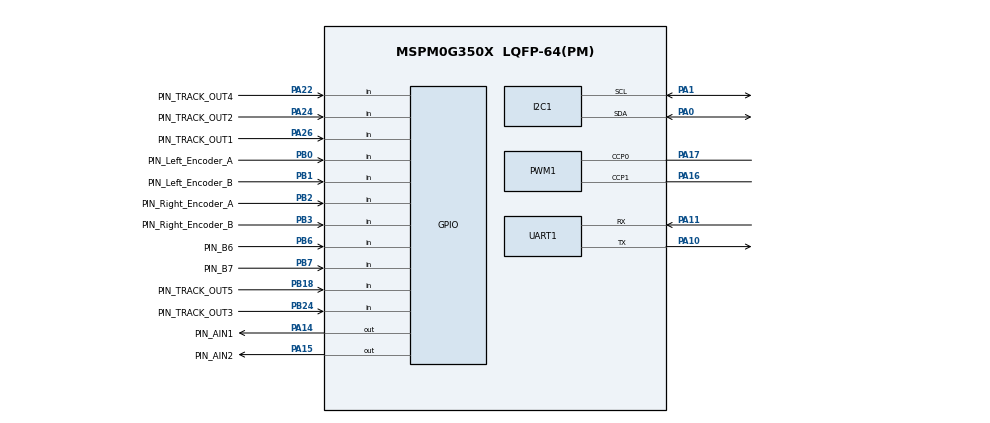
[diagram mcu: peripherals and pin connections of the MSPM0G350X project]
/**
 * @cliArgs --device "MSPM0G350X" --part "Default" --package "LQFP-64(PM)" --product "mspm0_sdk@2.10.00.04"
 * @versions {"tool":"1.26.2+4477"}
 */

/**
 * Import the modules used in this configuration.
 */
const Board  = scripting.addModule("/ti/driverlib/Board");
const GPIO   = scripting.addModule("/ti/driverlib/GPIO", {}, false);
const GPIO1  = GPIO.addInstance();
const GPIO2  = GPIO.addInstance();
const GPIO3  = GPIO.addInstance();
const GPIO4  = GPIO.addInstance();
const GPIO5  = GPIO.addInstance();
const GPIO6  = GPIO.addInstance();
const GPIO7  = GPIO.addInstance();
const GPIO8  = GPIO.addInstance();
const GPIO9  = GPIO.addInstance();
const GPIO10 = GPIO.addInstance();
const GPIO11 = GPIO.addInstance();
const GPIO12 = GPIO.addInstance();
const GPIO13 = GPIO.addInstance();
const GPIO14 = GPIO.addInstance();
const GPIO15 = GPIO.addInstance();
const GPIO16 = GPIO.addInstance();
const I2C    = scripting.addModule("/ti/driverlib/I2C", {}, false);
const I2C1   = I2C.addInstance();
const PWM    = scripting.addModule("/ti/driverlib/PWM", {}, false);
const PWM1   = PWM.addInstance();
const SYSCTL = scripting.addModule("/ti/driverlib/SYSCTL");
const TIMER  = scripting.addModule("/ti/driverlib/TIMER", {}, false);
const TIMER1 = TIMER.addInstance();
const UART   = scripting.addModule("/ti/driverlib/UART", {}, false);
const UART1  = UART.addInstance();

/**
 * Write custom configuration values to the imported modules.
 */
const divider9       = system.clockTree["UDIV"];
divider9.divideValue = 2;

const mux4       = system.clockTree["EXHFMUX"];
mux4.inputSelect = "EXHFMUX_XTAL";

const mux8       = system.clockTree["HSCLKMUX"];
mux8.inputSelect = "HSCLKMUX_SYSPLL2X";

const mux12       = system.clockTree["SYSPLLMUX"];
mux12.inputSelect = "zSYSPLLMUX_HFCLK";

const pinFunction4        = system.clockTree["HFXT"];
pinFunction4.inputFreq    = 40;
pinFunction4.enable       = true;
pinFunction4.HFXTStartup  = 10;
pinFunction4.HFCLKMonitor = true;


GPIO1.$name                              = "LED1";
GPIO1.port                               = "PORTB";
GPIO1.associatedPins[0].internalResistor = "PULL_DOWN";
GPIO1.associatedPins[0].$name            = "PIN_B22";
GPIO1.associatedPins[0].assignedPin      = "22";

GPIO2.$name                         = "AIN1";
GPIO2.port                          = "PORTA";
GPIO2.associatedPins[0].$name       = "PIN_AIN1";
GPIO2.associatedPins[0].pin.$assign = "PA14";

GPIO3.$name                         = "AIN2";
GPIO3.port                          = "PORTA";
GPIO3.associatedPins[0].$name       = "PIN_AIN2";
GPIO3.associatedPins[0].pin.$assign = "PA15";

GPIO4.$name                   = "BIN1";
GPIO4.port                    = "PORTA";
GPIO4.associatedPins[0].$name = "PIN_BIN1";

GPIO5.$name                   = "BIN2";
GPIO5.port                    = "PORTA";
GPIO5.associatedPins[0].$name = "PIN_BIN2";

GPIO6.port                               = "PORTB";
GPIO6.$name                              = "Left_Encoder_A";
GPIO6.associatedPins[0].direction        = "INPUT";
GPIO6.associatedPins[0].polarity         = "RISE";
GPIO6.associatedPins[0].interruptEn      = true;
GPIO6.associatedPins[0].$name            = "PIN_Left_Encoder_A";
GPIO6.associatedPins[0].internalResistor = "PULL_UP";
GPIO6.associatedPins[0].pin.$assign      = "PB0";

GPIO7.$name                              = "Right_Encoder_A";
GPIO7.port                               = "PORTB";
GPIO7.associatedPins[0].$name            = "PIN_Right_Encoder_A";
GPIO7.associatedPins[0].direction        = "INPUT";
GPIO7.associatedPins[0].interruptEn      = true;
GPIO7.associatedPins[0].polarity         = "RISE";
GPIO7.associatedPins[0].internalResistor = "PULL_UP";
GPIO7.associatedPins[0].pin.$assign      = "PB2";

GPIO8.$name                              = "Left_Encoder_B";
GPIO8.port                               = "PORTB";
GPIO8.associatedPins[0].$name            = "PIN_Left_Encoder_B";
GPIO8.associatedPins[0].direction        = "INPUT";
GPIO8.associatedPins[0].internalResistor = "PULL_UP";
GPIO8.associatedPins[0].pin.$assign      = "PB1";

GPIO9.$name                              = "Right_Encoder_B";
GPIO9.port                               = "PORTB";
GPIO9.associatedPins[0].$name            = "PIN_Right_Encoder_B";
GPIO9.associatedPins[0].direction        = "INPUT";
GPIO9.associatedPins[0].internalResistor = "PULL_UP";
GPIO9.associatedPins[0].pin.$assign      = "PB3";

GPIO10.$name                              = "KEY1";
GPIO10.port                               = "PORTB";
GPIO10.associatedPins[0].$name            = "PIN_B6";
GPIO10.associatedPins[0].direction        = "INPUT";
GPIO10.associatedPins[0].internalResistor = "PULL_DOWN";
GPIO10.associatedPins[0].pin.$assign      = "PB6";

GPIO11.$name                              = "KEY2";
GPIO11.port                               = "PORTB";
GPIO11.associatedPins[0].$name            = "PIN_B7";
GPIO11.associatedPins[0].direction        = "INPUT";
GPIO11.associatedPins[0].internalResistor = "PULL_DOWN";
GPIO11.associatedPins[0].pin.$assign      = "PB7";

/*
 * 5路 GPIO 循迹恢复备份：
 * TRACK_OUT1 = PA26
 * TRACK_OUT2 = PA24
 * TRACK_OUT3 = PB24
 * TRACK_OUT4 = PA22
 * TRACK_OUT5 = PB18
 *
 * 当前 8路红外循迹模块使用软件 I2C：
 * SCL = PA26, SDA = PA24。
 * Hardware/track.c 会在 Track_Init() 中把 PA26/PA24 重新配置为
 * 软件 I2C 开漏模拟引脚；这里保留旧配置作为后续恢复参考。
 */
GPIO12.$name                         = "TRACK_OUT1";
GPIO12.port                          = "PORTA";
GPIO12.associatedPins[0].$name       = "PIN_TRACK_OUT1";
GPIO12.associatedPins[0].direction   = "INPUT";
GPIO12.associatedPins[0].pin.$assign = "PA26";

GPIO13.$name                         = "TRACK_OUT2";
GPIO13.port                          = "PORTA";
GPIO13.associatedPins[0].$name       = "PIN_TRACK_OUT2";
GPIO13.associatedPins[0].direction   = "INPUT";
GPIO13.associatedPins[0].pin.$assign = "PA24";

GPIO14.$name                         = "TRACK_OUT3";
GPIO14.port                          = "PORTB";
GPIO14.associatedPins[0].$name       = "PIN_TRACK_OUT3";
GPIO14.associatedPins[0].direction   = "INPUT";
GPIO14.associatedPins[0].pin.$assign = "PB24";

GPIO15.$name                         = "TRACK_OUT4";
GPIO15.port                          = "PORTA";
GPIO15.associatedPins[0].$name       = "PIN_TRACK_OUT4";
GPIO15.associatedPins[0].direction   = "INPUT";
GPIO15.associatedPins[0].pin.$assign = "PA22";

GPIO16.$name                         = "TRACK_OUT5";
GPIO16.port                          = "PORTB";
GPIO16.associatedPins[0].$name       = "PIN_TRACK_OUT5";
GPIO16.associatedPins[0].direction   = "INPUT";
GPIO16.associatedPins[0].pin.$assign = "PB18";

I2C1.$name                     = "I2C_0";
I2C1.basicEnableController     = true;
I2C1.basicControllerBusSpeed   = 100000;
I2C1.peripheral.$assign        = "I2C0";
I2C1.peripheral.sdaPin.$assign = "PA0";
I2C1.peripheral.sclPin.$assign = "PA1";
I2C1.sdaPinConfig.$name        = "ti_driverlib_gpio_GPIOPinGeneric0";
I2C1.sdaPinConfig.enableConfig = true;
I2C1.sclPinConfig.$name        = "ti_driverlib_gpio_GPIOPinGeneric1";
I2C1.sclPinConfig.enableConfig = true;

PWM1.timerCount                         = 1600;
PWM1.timerStartTimer                    = true;
PWM1.$name                              = "PWM";
PWM1.peripheral.$assign                 = "TIMA1";
PWM1.peripheral.ccp0Pin.$assign         = "PA17";
PWM1.peripheral.ccp1Pin.$assign         = "PA16";
PWM1.PWM_CHANNEL_0.$name                = "ti_driverlib_pwm_PWMTimerCC0";
PWM1.PWM_CHANNEL_1.$name                = "ti_driverlib_pwm_PWMTimerCC1";
PWM1.ccp0PinConfig.$name                = "ti_driverlib_gpio_GPIOPinGeneric2";
PWM1.ccp0PinConfig.direction            = scripting.forceWrite("OUTPUT");
PWM1.ccp0PinConfig.hideOutputInversion  = scripting.forceWrite(false);
PWM1.ccp0PinConfig.onlyInternalResistor = scripting.forceWrite(false);
PWM1.ccp0PinConfig.passedPeripheralType = scripting.forceWrite("Digital");
PWM1.ccp1PinConfig.$name                = "ti_driverlib_gpio_GPIOPinGeneric3";
PWM1.ccp1PinConfig.direction            = scripting.forceWrite("OUTPUT");
PWM1.ccp1PinConfig.hideOutputInversion  = scripting.forceWrite(false);
PWM1.ccp1PinConfig.onlyInternalResistor = scripting.forceWrite(false);
PWM1.ccp1PinConfig.passedPeripheralType = scripting.forceWrite("Digital");

SYSCTL.forceDefaultClkConfig = true;
SYSCTL.clockTreeEn           = true;

TIMER1.$name              = "TIMER_SPEED";
TIMER1.timerClkDiv        = 8;
TIMER1.timerClkPrescale   = 10;
TIMER1.timerMode          = "PERIODIC";
TIMER1.timerPeriod        = "20 ms";
TIMER1.timerStartTimer    = true;
TIMER1.interrupts         = ["ZERO"];
TIMER1.peripheral.$assign = "TIMA0";

UART1.$name                    = "UART_0";
UART1.enabledInterrupts        = ["TX"];
UART1.peripheral.$assign       = "UART0";
UART1.peripheral.rxPin.$assign = "PA11";
UART1.peripheral.txPin.$assign = "PA10";
UART1.txPinConfig.$name        = "ti_driverlib_gpio_GPIOPinGeneric4";
UART1.rxPinConfig.$name        = "ti_driverlib_gpio_GPIOPinGeneric5";

/**
 * Pinmux solution for unlocked pins/peripherals. This ensures that minor changes to the automatic solver in a future
 * version of the tool will not impact the pinmux you originally saw.  These lines can be completely deleted in order to
 * re-solve from scratch.
 */
pinFunction4.peripheral.$suggestSolution           = "SYSCTL";
pinFunction4.peripheral.hfxInPin.$suggestSolution  = "PA5";
pinFunction4.peripheral.hfxOutPin.$suggestSolution = "PA6";
Board.peripheral.$suggestSolution                  = "DEBUGSS";
Board.peripheral.swclkPin.$suggestSolution         = "PA20";
Board.peripheral.swdioPin.$suggestSolution         = "PA19";
GPIO1.associatedPins[0].pin.$suggestSolution       = "PB22";
GPIO4.associatedPins[0].pin.$suggestSolution       = "PA13";
GPIO5.associatedPins[0].pin.$suggestSolution       = "PA12";
GPIO10.associatedPins[0].pin.$suggestSolution      = "PB6";
GPIO11.associatedPins[0].pin.$suggestSolution      = "PB7";
GPIO12.associatedPins[0].pin.$suggestSolution      = "PA26";
GPIO13.associatedPins[0].pin.$suggestSolution      = "PA24";
GPIO14.associatedPins[0].pin.$suggestSolution      = "PB24";
GPIO15.associatedPins[0].pin.$suggestSolution      = "PA22";
GPIO16.associatedPins[0].pin.$suggestSolution      = "PB18";
